# RZT2ME register map
Vendor: Renesas Electronics Corporation; Series: RZT; File version: 1.00.00
CPU: other r0p0, little endian, MPU, no FPU, VTOR, 4 interrupt priority bits, 624 interrupts
Registers are 32-bit, read-write, reset 0x0 unless marked. A register's access mark holds for its fields unless they carry their own. Offsets are from the block's base; [hi:lo] are bit positions; {n}, {i} and the like mark numbered series.

## RTC — Real Time Clock
Base 0x81009000
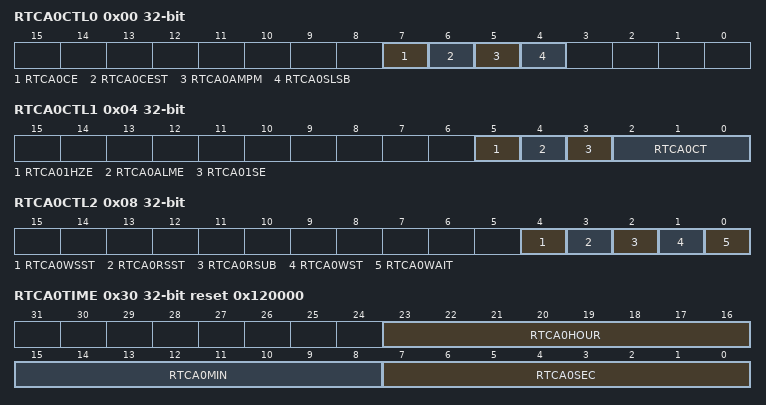
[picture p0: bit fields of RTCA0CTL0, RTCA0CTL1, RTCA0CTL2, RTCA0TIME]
0x00 RTCA0CTL0 — RTC Control Register 0
  [7] RTCA0CE — RTC Controller Enable Bit
    0=Clock counter operation stopped; 1=Clock counter operation enabled (the clock counter counts up)
  [6] RTCA0CEST ro — RTC Controller Enable Status
    0=Clock counter operation stopped status; 1=Clock counter operation enabled status (the clock counter counts up)
  [5] RTCA0AMPM — RTCA0HOUR, RTCA0ALH display format selection bit
    0=12-hour display; 1=24-hour display
  [4] RTCA0SLSB — RTCA0SCMP enable/disable setting
0x04 RTCA0CTL1 — RTC Control Register 1
  [5] RTCA01HZE — This bit enables/disables 1 Hz pulse output (RTCAT1HZ).
    0=Disable 1 Hz pulse output (RTCAT1HZ fixed to 0); 1=Enable 1 Hz pulse output
  [4] RTCA0ALME — Alarm interrupt (RTC_ALM) output enable bit
    0=Disable; 1=Enable
  [3] RTCA01SE — 1 second interrupt (RTC_1S) output enable bit
    0=Stop interrupt output at every 1 second; 1=Enable interrupt output at every 1 second
  [2:0] RTCA0CT — Fixed interval interrupt (RTC_PRD) output setting bit
    0=Fixed interval interrupt output stop; 1=Interrupt once every 0.25 seconds (in synchronization with second count-up); 2=Interrupt once every 0.5 seconds (in synchronization with second count-up); 3=Interrupt once every 1 second (in synchronization with second count-up); 4=Interrupt once every 1 minute (every 1 minute 00 seconds); 5=Interrupt once every 1 hour (every 1 hour 00 minutes 00 seconds); 6=Interrupt once every 1 day (every 1 day 00 hours 00 minutes 00 seconds); 7=Interrupt once every 1 month (every 1 month first day 00 hours 00 minutes 00 seconds a.m.)
0x08 RTCA0CTL2 — RTC Control Register 2
  [4] RTCA0WSST ro — RTCA0SCMP Write Status
    0=RTCA0SCMP write completed; 1=RTCA0SCMP write in progress
  [3] RTCA0RSST ro — RTCA0SRBU Transfer Status
    0=RTCA0SRBU data hold status; 1=Transfer of the value of RTCA0SUBC to RTCA0SRBU completed
  [2] RTCA0RSUB — RTCA0SUBC Data Transfer Control
    0=RTCA0SRBU data hold; 1=Transfer of value of RTCA0SUBC to RTCA0SRBU
  [1] RTCA0WST ro — RTC Controller Counter Wait Status
    0=Count-up status of RTCA0SECC, RTCA0MINC, RTCA0HOURC, RTCA0WEEKC, RTCA0DAYC, RTCA0MONC, RTCA0YEARC; 1=Count-up stopped status of RTCA0SECC, RTCA0MINC, RTCA0HOURC, RTCA0WEEKC, RTCA0DAYC, RTCA0MONC, RTCA0YEARC (count-up operation of second, minute, hour, week, day, month, and year count registers is stopped)
  [0] RTCA0WAIT — RTC Controller Counter Wait Control
    0=Counter operation; 1=Count-up operation of RTCA0SEC, RTCA0MIN, RTCA0HOUR, RTCA0WEEK, RTCA0DAY, RTCA0MONTH, RTCA0YEAR is stopped (count-up operation of second, minute, hour, week, day, month, and year count registers is stopped)
0x0C RTCA0SUBC ro — RTC Sub Count Register
  [21:0] RTCA0SUBC — Register that counts the 1 second reference time
0x10 RTCA0SRBU ro — RTC Sub Count Register Read Buffer
  [21:0] RTCA0SRBU — Read buffer register of RTCA0SUBC
0x14 RTCA0SEC — RTC Sec Count Buffer Register
  [6:0] RTCA0SEC — Buffer register to read/write RTC Second Count register (RTCA0SECC).
0x18 RTCA0MIN — RTC Min Count Buffer Register
  [6:0] RTCA0MIN — Buffer register to read/write RTC Minute Count register (RTCA0MINC).
0x1C RTCA0HOUR reset 0x12 — RTC Hour Count Buffer Register
  [5:0] RTCA0HOUR — Buffer register to read/write RTC Hour Count register (RTCA0HOURC).
0x20 RTCA0WEEK — RTC Week Count Buffer Register
  [2:0] RTCA0WEEK — Buffer register to read/write RTC Week Count register (RTCA0WEEKC).
0x24 RTCA0DAY reset 0x1 — RTC Day Count Buffer Register
  [5:0] RTCA0DAY — Buffer register to read/write RTC Day Count register (RTCA0DAYC).
0x28 RTCA0MONTH reset 0x1 — RTC Month Count Buffer Register
  [4:0] RTCA0MONTH — Buffer register to read/write RTC Month Count register (RTCA0MONC).
0x2C RTCA0YEAR — RTC Year Count Buffer Register
  [7:0] RTCA0YEAR — Buffer register to read/write RTC Year Count register (RTCA0YEARC).
0x30 RTCA0TIME reset 0x120000 — RTC Time Set Register
  [23:16] RTCA0HOUR — See RTCA0HOUR register
  [15:8] RTCA0MIN — See RTCA0MIN register
  [7:0] RTCA0SEC — See RTCA0SEC register
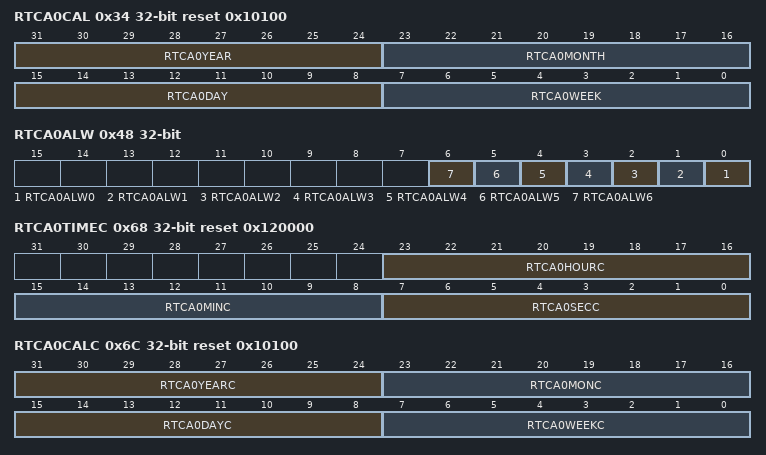
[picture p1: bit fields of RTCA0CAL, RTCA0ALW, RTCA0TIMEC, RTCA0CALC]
0x34 RTCA0CAL reset 0x10100 — RTC Calendar Set Register
  [31:24] RTCA0YEAR — See RTCA0YEAR register
  [23:16] RTCA0MONTH — See RTCA0MONTH register
  [15:8] RTCA0DAY — See RTCA0DAY register
  [7:0] RTCA0WEEK — See RTCA0WEEK register
0x3C RTCA0SCMP — RTC Sub Count Compare Register
  [21:0] RTCA0SCMP — Register that sets the compare value of RTCA0SUBC (sub-counter).
0x40 RTCA0ALM — RTC Alarm Min Set Register
  [6:0] RTCA0ALM — RTCA0ALM is a register that performs the minute setting for the alarm interrupt.
0x44 RTCA0ALH reset 0x12 — RTC Alarm Hour Set Register
  [5:0] RTCA0ALH — RTCA0ALH is a register that performs the hour setting for the alarm interrupt.
0x48 RTCA0ALW — RTC Alarm Week Set Register
  [all] fields
    0=Disable alarm; 1=Enable alarm
  [n] RTCA0ALW{n} (n=0..6) — Alarm interrupt day of the week setting bit {n}
0x4C RTCA0SECC ro — RTC Second Count Register
  [6:0] RTCA0SECC — Counts up the seconds
0x50 RTCA0MINC ro — RTC Minute Count Register
  [6:0] RTCA0MINC — Counts up the minutes
0x54 RTCA0HOURC ro reset 0x12 — RTC Hour Count Register
  [5:0] RTCA0HOURC — Counts up the hours
0x58 RTCA0WEEKC ro — RTC Week Count Register
  [2:0] RTCA0WEEKC — Counts up the weeks
0x5C RTCA0DAYC ro reset 0x1 — RTC Day Count Register
  [5:0] RTCA0DAYC — Counts up the days
0x60 RTCA0MONC ro reset 0x1 — RTC Month Count Register
  [4:0] RTCA0MONC — Counts up the months
0x64 RTCA0YEARC ro — RTC Year Count Register
  [7:0] RTCA0YEARC — Counts up the years
0x68 RTCA0TIMEC ro reset 0x120000 — RTC Time Count Register
  [23:16] RTCA0HOURC — See RTCA0HOURC register
  [15:8] RTCA0MINC — See RTCA0MINC register
  [7:0] RTCA0SECC — See RTCA0SECC register
0x6C RTCA0CALC ro reset 0x10100 — RTC Calendar Count Register
  [31:24] RTCA0YEARC — See RTCA0YEARC register
  [23:16] RTCA0MONC — See RTCA0MONC register
  [15:8] RTCA0DAYC — See RTCA0DAYC register
  [7:0] RTCA0WEEKC — See RTCA0WEEKC register
